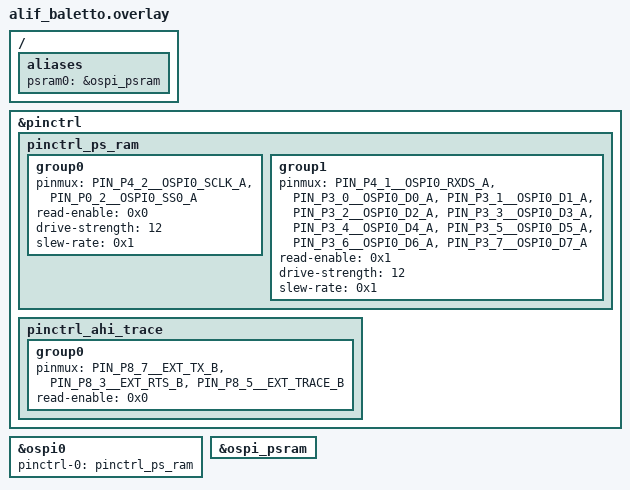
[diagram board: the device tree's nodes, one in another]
/{
        aliases {
		psram0 = &ospi_psram;
	};
};

&pinctrl {
	//PSRAM connected with "PIN_P0_2__OSPI0_SS0_A" CS line
	pinctrl_ps_ram:pinctrl_ps_ram {
		group0 {
			pinmux = <PIN_P4_2__OSPI0_SCLK_A>,
				 <PIN_P0_2__OSPI0_SS0_A>;
			read-enable = <0x0>;
			drive-strength = <12>;
			slew-rate = <0x1>;
		};
		group1 {
			pinmux = <PIN_P4_1__OSPI0_RXDS_A>,
				 <PIN_P3_0__OSPI0_D0_A>,
				 <PIN_P3_1__OSPI0_D1_A>,
				 <PIN_P3_2__OSPI0_D2_A>,
				 <PIN_P3_3__OSPI0_D3_A>,
				 <PIN_P3_4__OSPI0_D4_A>,
				 <PIN_P3_5__OSPI0_D5_A>,
				 <PIN_P3_6__OSPI0_D6_A>,
				 <PIN_P3_7__OSPI0_D7_A>;
			read-enable = <0x1>;
			drive-strength = <12>;
			slew-rate = <0x1>;
		};
	};

	//Default AHI Trace pins affects OSPI-Flash pins.
	pinctrl_ahi_trace: pinctrl_ahi_trace {
		group0 {
			pinmux = <PIN_P8_7__EXT_TX_B>,
				 <PIN_P8_3__EXT_RTS_B>,
				 <PIN_P8_5__EXT_TRACE_B>;
			read-enable = < 0x0 >;
		};
	};
};

&ospi0 {
	pinctrl-0 = <&pinctrl_ps_ram>;
	status = "okay";
};

&ospi_psram {
	status = "okay";
};
